# IMC300A register map
Vendor: Infineon; File version: 1.0.0
CPU: CM0 r0p0, little endian, no MPU, no FPU, 2 interrupt priority bits
Registers are 32-bit, read-write, reset 0x0 unless marked. A register's access mark holds for its fields unless they carry their own. Offsets are from the block's base; [hi:lo] are bit positions; lines under a group give offsets from that group; {n}, {i} and the like mark numbered series; 'fields as' and 'values as' point back to an identical list.

## ADC — Analog to Digital Converter
Base 0x48030000
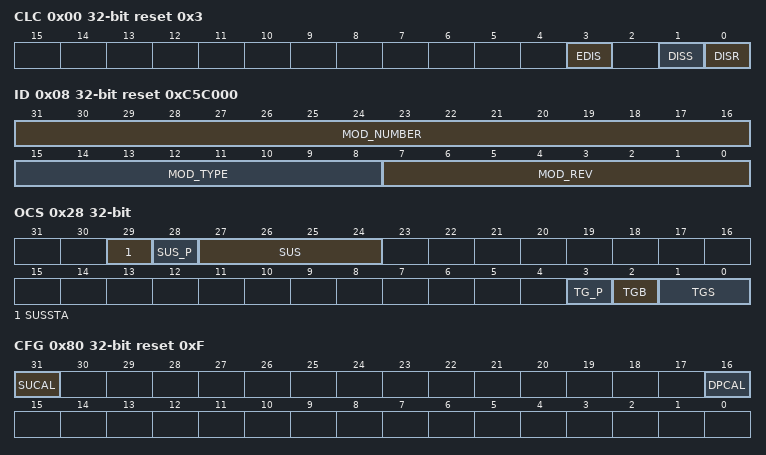
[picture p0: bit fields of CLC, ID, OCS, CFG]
0x00 CLC access per field reset 0x3 — Clock Control Register
  [3] EDIS rw — Sleep Mode Enable Control
    0=Sleep mode request is enabled and functional; 1=Module disregards the sleep mode control signal
  [1] DISS ro — Module Disable Status Bit
    0=Module clock is enabled; 1=Off: module is not clocked
  [0] DISR rw — Module Disable Request Bit
    0=On request: enable the module clock; 1=Off request: stop the module clock
0x08 ID ro reset 0xC5C000 (reset mask 0xFFFFFF00) — Module Identification Register
  [31:16] MOD_NUMBER — Module Number
  [15:8] MOD_TYPE — Module Type
  [7:0] MOD_REV — Module Revision
0x28 OCS access per field — OCDS Control and Status Register
  [29] SUSSTA ro — Suspend State
    0=Module is not (yet) suspended; 1=Module is suspended
  [28] SUS_P wo — SUS Write Protection
  [27:24] SUS rw — OCDS Suspend Control
    0=Will not suspend; 1=Hard suspend: Clock is switched off immediately; 2=Soft suspend mode 0: Stop after this conversion and keep arbiter running; 3=Soft suspend mode 1: Stop after this conversion and stop arbiter after this round
  [3] TG_P wo — TGS, TGB Write Protection
  [2] TGB rw — OTGB0/1 Bus Select
    0=Trigger Set is output on OTGB0; 1=Trigger Set is output on OTGB1
  [1:0] TGS rw — Trigger Set for OTGB0/1
    0=No Trigger Set output; 1=Trigger Set 1: TS16_SSIG, input sample signals
0x80 CFG access per field reset 0xF — Configuration Register
  [31] SUCAL wo — Start-Up Calibration
    0=No action; 1=Initiate start-up calibration
  [16] DPCAL rw — Disable Post-Calibration
    0=Automatic post-calibration after each conversion of group x; 1=No post-calibration
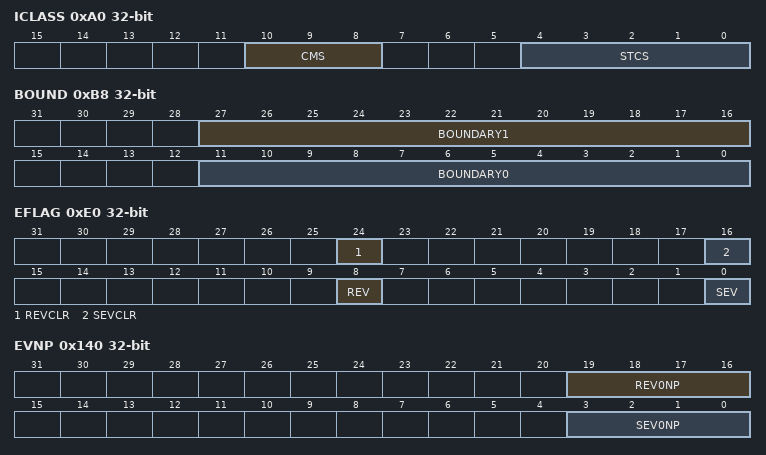
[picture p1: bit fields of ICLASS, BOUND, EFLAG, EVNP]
0xA0 ICLASS — Input Class Register
  [10:8] CMS — Conversion Mode for Standard Conversions
    0=12-bit conversion; 1=10-bit conversion; 2=8-bit conversion; 5=10-bit fast compare mode
  [4:0] STCS — Sample Time Control for Standard Conversions
0xB8 BOUND — Boundary Select Register
  [27:16] BOUNDARY1 — Boundary Value 1 for Limit Checking
  [11:0] BOUNDARY0 — Boundary Value 0 for Limit Checking
0xE0 EFLAG access per field — Event Flag Register
  [24] REVCLR wo — Clear Result Event
    0=No action; 1=Clear the result event flag REV
  [16] SEVCLR wo — Clear Source Event
    0=No action; 1=Clear the source event flag SEVGLB
  [8] REV rw — Result Event
    0=No result event; 1=New result was stored in register RES
  [0] SEV rw — Source Event
    0=No source event; 1=A source event has occurred
0x140 EVNP — Event Node Pointer Register
  [19:16] REV0NP — Service Request Node Pointer Result
    0=Select shared service request line 0 of common service request group 0; 3=Select shared service request line 3 of common service request group 0
  [3:0] SEV0NP — Service Request Node Pointer Backgr. Source
    values as REV0NP
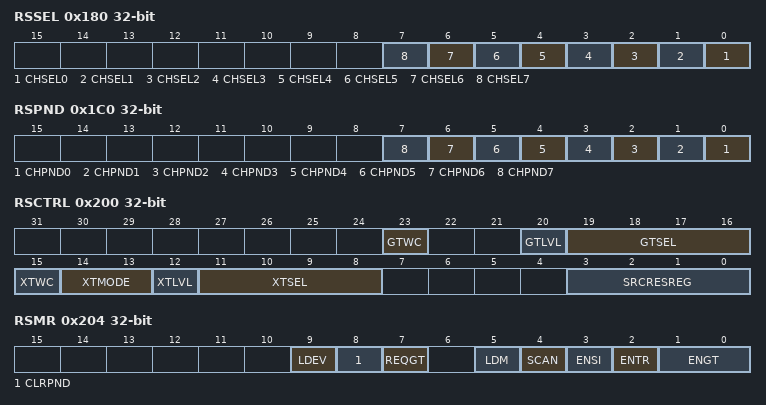
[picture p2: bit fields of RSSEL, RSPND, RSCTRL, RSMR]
0x180 RSSEL — Request Source Channel Select Register
  [all] fields
    0=Ignore this channel; 1=This channel is part of the scan sequence
  [n] CHSEL{n} (n=0..7) — Channel Selection {n}
0x1C0 RSPND — Request Source Pending Register
  [all] fields
    0=Ignore this channel; 1=Request conversion of this channel
  [n] CHPND{n} (n=0..7) — Channels Pending {n}
0x200 RSCTRL access per field — Request Source Control Register
  [23] GTWC wo — Write Control for Gate Configuration
    0=No write access to gate configuration; 1=Bitfield GTSEL can be written
  [20] GTLVL ro — Gate Input Level
  [19:16] GTSEL rw — Gate Input Selection
  [15] XTWC wo — Write Control for Trigger Configuration
    0=No write access to trigger configuration; 1=Bitfields XTMODE and XTSEL can be written
  [14:13] XTMODE rw — Trigger Operating Mode
    0=No external trigger; 1=Trigger event upon a falling edge; 2=Trigger event upon a rising edge; 3=Trigger event upon any edge
  [12] XTLVL ro — External Trigger Level
  [11:8] XTSEL rw — External Trigger Input Selection
  [3:0] SRCRESREG rw — Source-specific Result Register
    0=Use GxCHCTRy.RESREG to select a group result register; 1=Store result in group result register GxRES1; 15=Store result in group result register GxRES15
0x204 RSMR access per field — Request Source Mode Register
  [9] LDEV wo — Generate Load Event
    0=No action; 1=A load event is generated
  [8] CLRPND wo — Clear Pending Bits
    0=No action; 1=The bits in registers BRSPNDx are cleared
  [7] REQGT ro — Request Gate Level
    0=The gate input is low; 1=The gate input is high
  [5] LDM rw — Autoscan Source Load Event Mode
    0=A load event copies all bits from the select register to the pending register; 1=A load event OR combines pending bits with select register bits
  [4] SCAN rw — Autoscan Enable
    0=No autoscan; 1=Autoscan functionality enabled
  [3] ENSI rw — Enable Source Interrupt
    0=No request source interrupt; 1=A request source interrupt is generated after last pending conversion is finished
  [2] ENTR rw — Enable External Trigger
    0=External trigger disabled; 1=External trigger enabled
  [1:0] ENGT rw — Enable Gate
    0=No conversion requests are issued; 1=Conversion requests issued by pending bits; 2=Conversion requests issued by pending bits and REQGTx is 1; 3=Conversion requests issued by pending bits and REQGTx is 0
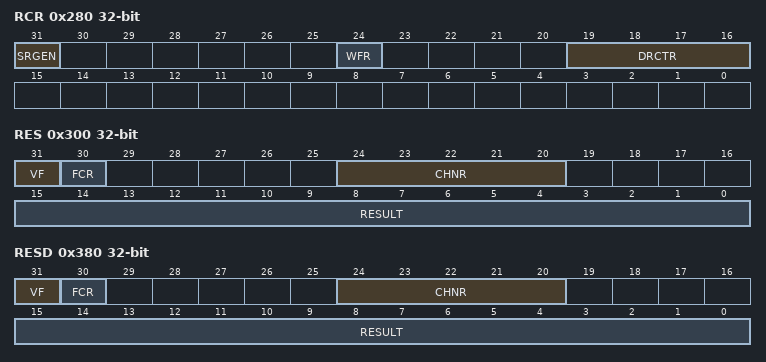
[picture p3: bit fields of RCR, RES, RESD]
0x280 RCR — Result Control Register
  [31] SRGEN — Service Request Generation Enable
    0=No service request; 1=Service request after a result event
  [24] WFR — Wait-for-Read Mode Enable
    0=Overwrite mode; 1=Wait-for-read mode enabled for this register
  [19:16] DRCTR — Data Reduction Control
    0=Data reduction disabled
0x300 RES access per field read-has-side-effects — Result Register
  [31] VF rw — Valid Flag
    0=Read access: No new valid data available - Write access: No effect; 1=Read access: Bitfield RESULT contains valid data - Write access: Clear this valid flag
  [30] FCR ro — Fast Compare Result
    0=Signal level was below compare value; 1=Signal level was above compare value
  [24:20] CHNR ro — Channel Number
  [15:0] RESULT rw — Result of most recent conversion
0x380 RESD access per field — Result Register, Debug
  [31] VF rw — Valid Flag
    0=Read access: No new valid data available - Write access: No effect (debug); 1=Read access: Bitfield RESULT contains valid data - Write access: Clear this valid flag (debug)
  [30] FCR ro — Fast Compare Result
    0=Signal level was below compare value (debug); 1=Signal level was above compare value (debug)
  [24:20] CHNR ro — Channel Number
  [15:0] RESULT rw — Result of most recent conversion
